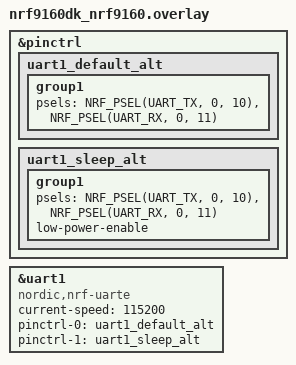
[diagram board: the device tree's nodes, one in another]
/* SPDX-License-Identifier: Apache-2.0 */

&pinctrl {
	uart1_default_alt: uart1_default_alt {
		group1 {
			psels = <NRF_PSEL(UART_TX, 0, 10)>,
				<NRF_PSEL(UART_RX, 0, 11)>;
		};
	};

	uart1_sleep_alt: uart1_sleep_alt {
		group1 {
			psels = <NRF_PSEL(UART_TX, 0, 10)>,
				<NRF_PSEL(UART_RX, 0, 11)>;
			low-power-enable;
		};
	};
};

dut: &uart1 {
	current-speed = <115200>;
	compatible = "nordic,nrf-uarte";
	status = "okay";
	pinctrl-0 = <&uart1_default_alt>;
	pinctrl-1 = <&uart1_sleep_alt>;
	pinctrl-names = "default", "sleep";
};
